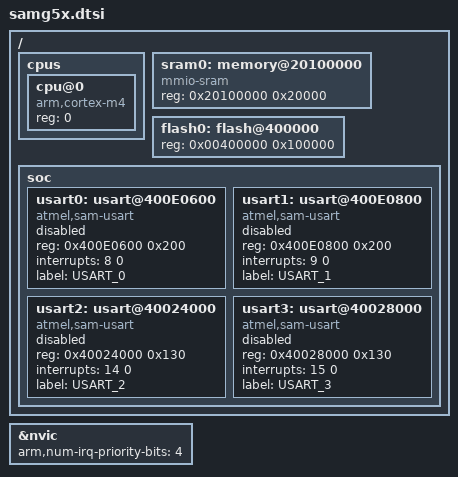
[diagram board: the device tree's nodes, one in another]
/*
 * Copyright (c) 2017 Justin Watson
 *
 * SPDX-License-Identifier: Apache-2.0
 */

#include <arm/armv7-m.dtsi>

/ {
	cpus {
		#address-cells = <1>;
		#size-cells = <0>;

		cpu@0 {
			device_type = "cpu";
			compatible = "arm,cortex-m4";
			reg = <0>;
		};
	};

	sram0: memory@20100000 {
		device_type = "memory";
		compatible = "mmio-sram";
		reg = <0x20100000 0x20000>;
	};

	flash0: flash@400000 {
		reg = <0x00400000 0x100000>;
	};

	soc {
		usart0: usart@400E0600 {
			compatible = "atmel,sam-usart";
			reg = <0x400E0600 0x200>;
			interrupts = <8 0>;
			status = "disabled";
			label = "USART_0";
		};

		usart1: usart@400E0800 {
			compatible = "atmel,sam-usart";
			reg = <0x400E0800 0x200>;
			interrupts = <9 0>;
			status = "disabled";
			label = "USART_1";
		};

		usart2: usart@40024000 {
			compatible = "atmel,sam-usart";
			reg = <0x40024000 0x130>;
			interrupts = <14 0>;
			status = "disabled";
			label = "USART_2";
		};

		usart3: usart@40028000 {
			compatible = "atmel,sam-usart";
			reg = <0x40028000 0x130>;
			interrupts = <15 0>;
			status = "disabled";
			label = "USART_3";
		};
	};
};

&nvic {
	arm,num-irq-priority-bits = <4>;
};
